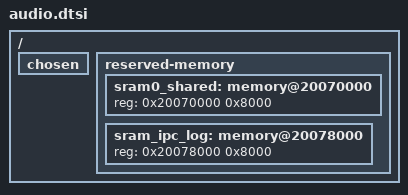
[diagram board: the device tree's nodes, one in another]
/ {
	chosen {
		/delete-property/ zephyr,ipc_shm;
	};

	reserved-memory {
		/delete-node/ memory@20070000;

		sram0_shared: memory@20070000 {
			reg = <0x20070000 0x8000>;
		};

		sram_ipc_log: memory@20078000 {
			reg = <0x20078000 0x8000>;
		};
	};
};
